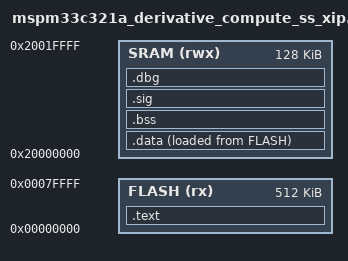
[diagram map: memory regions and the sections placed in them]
/*
 * Copyright (c) 2026 NC Factory
 * Author: NC MCU Factory Requirements Agent
 * License: Apache-2.0
 * Generated by: nc_socgen/scripts/gen_soc.py
 * Generator version: 1.1.0
 * Generation UTC: 2026-05-29T04:57:53.077343+00:00
 * Source config: /tmp/soc_config_gen.yaml
 * NOTE: Auto-generated file. Do not edit manually.
 */

ENTRY(_start)

MEMORY
{
    FLASH (rx)  : ORIGIN = 0x00000000, LENGTH = 0x00080000
    SRAM  (rwx) : ORIGIN = 0x20000000, LENGTH = 0x00020000
}

SECTIONS
{
    .text : {
        *(.text.start)
        *(.text*)
        *(.rodata*)
    } > FLASH

    .data : {
        _data_start = .;
        *(.data*)
        *(.sdata*)
        _data_end = .;
    } > SRAM AT > FLASH

    .bss : {
        _bss_start = .;
        *(.bss*)
        *(.sbss*)
        *(COMMON)
        _bss_end = .;
    } > SRAM

    _data_load = LOADADDR(.data);
    __sig_base = ORIGIN(SRAM) + LENGTH(SRAM) - 0x200;
    .sig __sig_base : {
        *(.sig*)
    } > SRAM
    __dbg_base = ORIGIN(SRAM) + LENGTH(SRAM) - 0x100;
    .dbg __dbg_base : {
        *(.dbg*)
    } > SRAM
    _stack_top = __sig_base;
}
